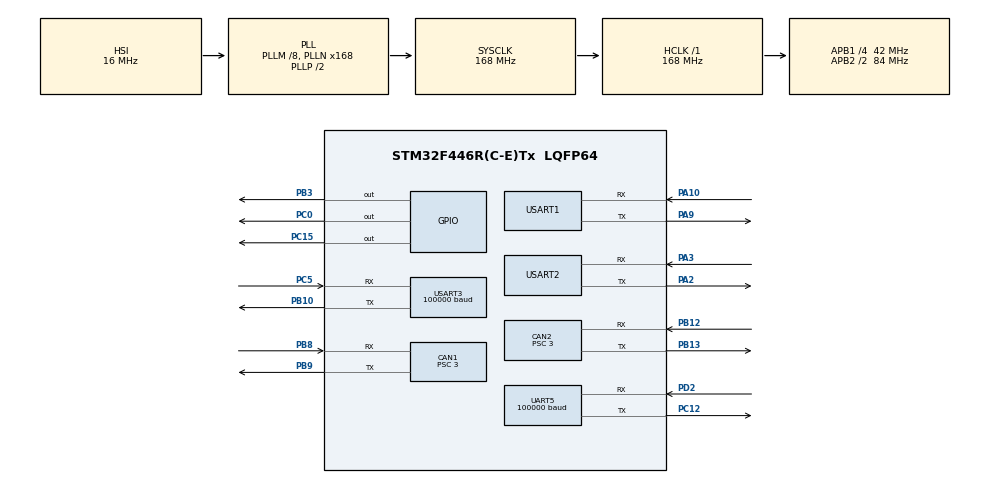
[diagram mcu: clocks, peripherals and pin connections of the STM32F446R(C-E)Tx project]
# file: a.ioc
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CAN1.BS1=CAN_BS1_9TQ
CAN1.BS2=CAN_BS2_4TQ
CAN1.CalculateBaudRate=1000000
CAN1.CalculateTimeBit=1000
CAN1.CalculateTimeQuantum=71.42857142857143
CAN1.Prescaler=3
CAN2.ABOM=ENABLE
CAN2.BS1=CAN_BS1_9TQ
CAN2.BS2=CAN_BS2_4TQ
CAN2.CalculateBaudRate=1000000
CAN2.CalculateTimeBit=1000
CAN2.CalculateTimeQuantum=71.42857142857143
CAN2.NART=ENABLE
CAN2.Prescaler=3
Dma.Request0=UART5_RX
Dma.Request1=USART2_RX
Dma.Request2=USART2_TX
Dma.Request3=USART3_RX
Dma.UART5_RX.0.Direction=DMA_PERIPH_TO_MEMORY
Dma.UART5_RX.0.FIFOMode=DMA_FIFOMODE_DISABLE
Dma.UART5_RX.0.Instance=DMA1_Stream0
Dma.UART5_RX.0.MemDataAlignment=DMA_MDATAALIGN_BYTE
Dma.UART5_RX.0.MemInc=DMA_MINC_ENABLE
Dma.UART5_RX.0.Mode=DMA_CIRCULAR
Dma.UART5_RX.0.PeriphDataAlignment=DMA_PDATAALIGN_BYTE
Dma.UART5_RX.0.PeriphInc=DMA_PINC_DISABLE
Dma.UART5_RX.0.Priority=DMA_PRIORITY_LOW
Dma.USART2_RX.1.Direction=DMA_PERIPH_TO_MEMORY
Dma.USART2_RX.1.FIFOMode=DMA_FIFOMODE_DISABLE
Dma.USART2_RX.1.Instance=DMA1_Stream5
Dma.USART2_RX.1.MemDataAlignment=DMA_MDATAALIGN_BYTE
Dma.USART2_RX.1.MemInc=DMA_MINC_ENABLE
Dma.USART2_RX.1.Mode=DMA_NORMAL
Dma.USART2_RX.1.PeriphDataAlignment=DMA_PDATAALIGN_BYTE
Dma.USART2_RX.1.PeriphInc=DMA_PINC_DISABLE
Dma.USART2_RX.1.Priority=DMA_PRIORITY_LOW
Dma.USART2_TX.2.Direction=DMA_MEMORY_TO_PERIPH
Dma.USART2_TX.2.FIFOMode=DMA_FIFOMODE_DISABLE
Dma.USART2_TX.2.Instance=DMA1_Stream6
Dma.USART2_TX.2.MemDataAlignment=DMA_MDATAALIGN_BYTE
Dma.USART2_TX.2.MemInc=DMA_MINC_ENABLE
Dma.USART2_TX.2.Mode=DMA_NORMAL
Dma.USART2_TX.2.PeriphDataAlignment=DMA_PDATAALIGN_BYTE
Dma.USART2_TX.2.PeriphInc=DMA_PINC_DISABLE
Dma.USART2_TX.2.Priority=DMA_PRIORITY_LOW
Dma.USART3_RX.3.Direction=DMA_PERIPH_TO_MEMORY
Dma.USART3_RX.3.FIFOMode=DMA_FIFOMODE_DISABLE
Dma.USART3_RX.3.Instance=DMA1_Stream1
Dma.USART3_RX.3.MemDataAlignment=DMA_MDATAALIGN_BYTE
Dma.USART3_RX.3.MemInc=DMA_MINC_ENABLE
Dma.USART3_RX.3.Mode=DMA_CIRCULAR
Dma.USART3_RX.3.PeriphDataAlignment=DMA_PDATAALIGN_BYTE
Dma.USART3_RX.3.PeriphInc=DMA_PINC_DISABLE
Dma.USART3_RX.3.Priority=DMA_PRIORITY_LOW
Mcu.Family=STM32F4
Mcu.Name=STM32F446R(C-E)Tx
Mcu.Package=LQFP64
NVIC.CAN1_RX0_IRQn=true\:0\:0\:false\:false\:true\:true\:true\:true
NVIC.CAN1_RX1_IRQn=true\:0\:0\:false\:false\:true\:true\:true\:true
NVIC.CAN2_RX0_IRQn=true\:0\:0\:false\:false\:true\:true\:true\:true
NVIC.CAN2_RX1_IRQn=true\:0\:0\:false\:false\:true\:true\:true\:true
NVIC.DMA1_Stream0_IRQn=true\:0\:0\:false\:false\:true\:false\:true\:true
NVIC.DMA1_Stream1_IRQn=true\:0\:0\:false\:false\:true\:false\:true\:true
NVIC.DMA1_Stream5_IRQn=true\:0\:0\:false\:false\:true\:false\:true\:true
NVIC.DMA1_Stream6_IRQn=true\:0\:0\:false\:false\:true\:false\:true\:true
NVIC.PriorityGroup=NVIC_PRIORITYGROUP_4
NVIC.TIM2_IRQn=true\:0\:0\:false\:false\:true\:true\:true\:true
NVIC.UART5_IRQn=true\:0\:0\:false\:false\:true\:true\:true\:true
NVIC.USART1_IRQn=true\:0\:0\:false\:false\:true\:true\:true\:true
NVIC.USART2_IRQn=true\:0\:0\:false\:false\:true\:true\:true\:true
NVIC.USART3_IRQn=true\:0\:0\:false\:false\:true\:true\:true\:true
PA10.Mode=Asynchronous
PA10.Signal=USART1_RX
PA13.Mode=Serial_Wire
PA13.Signal=SYS_JTMS-SWDIO
PA14.Mode=Serial_Wire
PA14.Signal=SYS_JTCK-SWCLK
PA2.Mode=Asynchronous
PA2.Signal=USART2_TX
PA3.Mode=Asynchronous
PA3.Signal=USART2_RX
PA9.Mode=Asynchronous
PA9.Signal=USART1_TX
PB10.Mode=Asynchronous
PB10.Signal=USART3_TX
PB12.Mode=CAN_Activate
PB12.Signal=CAN2_RX
PB13.Mode=CAN_Activate
PB13.Signal=CAN2_TX
PB3.Signal=GPIO_Output
PB8.Mode=CAN_Activate
PB8.Signal=CAN1_RX
PB9.Mode=CAN_Activate
PB9.Signal=CAN1_TX
PC0.Signal=GPIO_Output
PC12.Mode=Asynchronous
PC12.Signal=UART5_TX
PC15-OSC32_OUT.Signal=GPIO_Output
PC5.Mode=Asynchronous
PC5.Signal=USART3_RX
PD2.Mode=Asynchronous
PD2.Signal=UART5_RX
PH0-OSC_IN.Mode=HSE-External-Oscillator
PH0-OSC_IN.Signal=RCC_OSC_IN
PH1-OSC_OUT.Mode=HSE-External-Oscillator
PH1-OSC_OUT.Signal=RCC_OSC_OUT
ProjectManager.HeapSize=0x200
ProjectManager.StackSize=0x400
ProjectManager.TargetToolchain=CMake
RCC.AHBFreq_Value=168000000
RCC.APB1CLKDivider=RCC_HCLK_DIV4
RCC.APB1Freq_Value=42000000
RCC.APB1TimFreq_Value=84000000
RCC.APB2CLKDivider=RCC_HCLK_DIV2
RCC.APB2Freq_Value=84000000
RCC.APB2TimFreq_Value=168000000
RCC.CortexFreq_Value=168000000
RCC.HCLKFreq_Value=168000000
RCC.PLLM=8
RCC.PLLN=168
RCC.SYSCLKFreq_VALUE=168000000
RCC.SYSCLKSource=RCC_SYSCLKSOURCE_PLLCLK
RCC.USBFreq_Value=168000000
RCC.VCOOutputFreq_Value=336000000
TIM2.AutoReloadPreload=TIM_AUTORELOAD_PRELOAD_ENABLE
TIM2.Period=100
TIM2.Prescaler=8400-1
UART5.BaudRate=100000
UART5.VirtualMode=Asynchronous
USART1.VirtualMode=VM_ASYNC
USART2.VirtualMode=VM_ASYNC
USART3.BaudRate=100000
USART3.Mode=MODE_RX
USART3.StopBits=STOPBITS_1
USART3.VirtualMode=VM_ASYNC
VP_TIM2_VS_ClockSourceINT.Mode=Internal
board=custom

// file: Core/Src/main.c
/* USER CODE BEGIN Header */
/**
  ******************************************************************************
  * @file           : main.c
  * @brief          : Main program body
  ******************************************************************************
  * @attention
  *
  * Copyright (c) 2025 STMicroelectronics.
  * All rights reserved.
  *
  * This software is licensed under terms that can be found in the LICENSE file
  * in the root directory of this software component.
  * If no LICENSE file comes with this software, it is provided AS-IS.
  *
  ******************************************************************************
  */
/* USER CODE END Header */
#include "main.h"
#include "can.h"
#include "dma.h"
#include "tim.h"
#include "usart.h"
#include "gpio.h"

/* USER CODE BEGIN Includes */
#include "motor_conf.h"
#include "init_task.h"
#include "FreeRTOS.h"
#include "task.h"

/* USER CODE END Includes */

void SystemClock_Config(void);

/* USER CODE BEGIN 0 */

// // 定义点灯任务的优先级
// #define LED_TASK_PRIORITY (configMAX_PRIORITIES - 1)
// // 定义点灯任务的堆栈大小
// #define LED_TASK_STACK_SIZE 128

// // 点灯任务函数
// void LedTask(void *pvParameters)
// {
//     while (1)
//     {
//       // 点亮LED
//         HAL_GPIO_WritePin(GPIOC, GPIO_PIN_0, GPIO_PIN_RESET);
//         // 延时一段时间
//         vTaskDelay(pdMS_TO_TICKS(500));
//         // 熄灭LED
//         HAL_GPIO_WritePin(GPIOC,GPIO_PIN_0, GPIO_PIN_SET);
//         // 再延时一段时间
//         vTaskDelay(pdMS_TO_TICKS(500));
//     }
// }
/* USER CODE END 0 */

int main(void)
{

  /* MCU Configuration--------------------------------------------------------*/

  /* Reset of all peripherals, Initializes the Flash interface and the Systick. */
  HAL_Init();

  /* Configure the system clock */
  SystemClock_Config();

  /* Initialize all configured peripherals */
  MX_GPIO_Init();
  MX_DMA_Init();
  MX_USART2_UART_Init();
  MX_CAN2_Init();
  MX_TIM2_Init();
  MX_USART1_UART_Init();
  MX_USART3_UART_Init();
  MX_CAN1_Init();
  MX_UART5_Init();
  /* USER CODE BEGIN 2 */

  robot_init();
//  // 初始化FreeRTOS

//  // 创建点灯任务
//   xTaskCreate(LedTask, "LedTask", LED_TASK_STACK_SIZE, NULL, LED_TASK_PRIORITY, NULL);

//  // 启动任务调度器
//   vTaskStartScheduler();
  /* USER CODE END 2 */

  /* Infinite loop */
  while (1)
  {

  }
}

void SystemClock_Config(void)
{
  RCC_OscInitTypeDef RCC_OscInitStruct = {0};
  RCC_ClkInitTypeDef RCC_ClkInitStruct = {0};

  /** Configure the main internal regulator output voltage
  */
  __HAL_RCC_PWR_CLK_ENABLE();
  __HAL_PWR_VOLTAGESCALING_CONFIG(PWR_REGULATOR_VOLTAGE_SCALE1);

  /** Initializes the RCC Oscillators according to the specified parameters
  * in the RCC_OscInitTypeDef structure.
  */
  RCC_OscInitStruct.OscillatorType = RCC_OSCILLATORTYPE_HSI;
  RCC_OscInitStruct.HSIState = RCC_HSI_ON;
  RCC_OscInitStruct.HSICalibrationValue = RCC_HSICALIBRATION_DEFAULT;
  RCC_OscInitStruct.PLL.PLLState = RCC_PLL_ON;
  RCC_OscInitStruct.PLL.PLLSource = RCC_PLLSOURCE_HSI;
  RCC_OscInitStruct.PLL.PLLM = 8;
  RCC_OscInitStruct.PLL.PLLN = 168;
  RCC_OscInitStruct.PLL.PLLP = RCC_PLLP_DIV2;
  RCC_OscInitStruct.PLL.PLLQ = 2;
  RCC_OscInitStruct.PLL.PLLR = 2;
  if (HAL_RCC_OscConfig(&RCC_OscInitStruct) != HAL_OK)
  {
    Error_Handler();
  }

  /** Initializes the CPU, AHB and APB buses clocks
  */
  RCC_ClkInitStruct.ClockType = RCC_CLOCKTYPE_HCLK|RCC_CLOCKTYPE_SYSCLK
                              |RCC_CLOCKTYPE_PCLK1|RCC_CLOCKTYPE_PCLK2;
  RCC_ClkInitStruct.SYSCLKSource = RCC_SYSCLKSOURCE_PLLCLK;
  RCC_ClkInitStruct.AHBCLKDivider = RCC_SYSCLK_DIV1;
  RCC_ClkInitStruct.APB1CLKDivider = RCC_HCLK_DIV4;
  RCC_ClkInitStruct.APB2CLKDivider = RCC_HCLK_DIV2;

  if (HAL_RCC_ClockConfig(&RCC_ClkInitStruct, FLASH_LATENCY_5) != HAL_OK)
  {
    Error_Handler();
  }
}

/* USER CODE BEGIN 4 */
void HAL_TIM_PeriodElapsedCallback(TIM_HandleTypeDef *htim)
{
    /* USER CODE BEGIN Callback 0 */

    /* USER CODE END Callback 0 */
    if (htim->Instance == TIM2 ){
      BaseType_t xHigherPriorityTaskWoken = pdFALSE;
      xSemaphoreGiveFromISR(xChassisSemaphore, &xHigherPriorityTaskWoken);
      portYIELD_FROM_ISR(xHigherPriorityTaskWoken);
    }
    /* USER CODE BEGIN Callback 1 */

    /* USER CODE END Callback 1 */
}
/* USER CODE END 4 */

void Error_Handler(void)
{
  __disable_irq();
  while (1)
  {
  }
}
